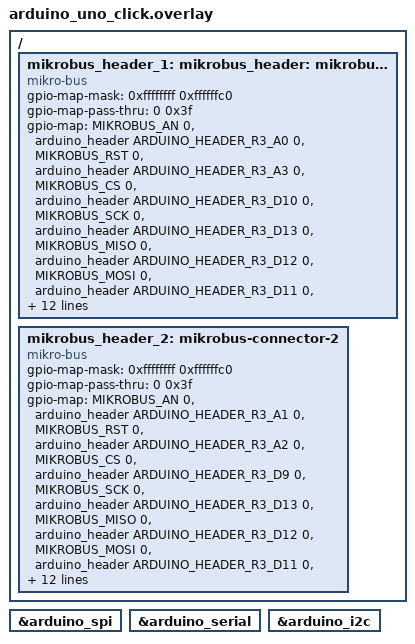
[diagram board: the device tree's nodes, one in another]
/*
 * Copyright (c) 2023 Andriy Gelman
 *
 * SPDX-License-Identifier: Apache-2.0
 */

#include <zephyr/dt-bindings/gpio/arduino-header-r3.h>
#include <zephyr/dt-bindings/gpio/mikro-bus.h>

/ {
	mikrobus_header_1: mikrobus-connector-1 {
		compatible = "mikro-bus";
		#gpio-cells = <2>;
		gpio-map-mask = <0xffffffff 0xffffffc0>;
		gpio-map-pass-thru = <0 0x3f>;
		gpio-map = <MIKROBUS_AN 0 &arduino_header ARDUINO_HEADER_R3_A0 0>,
			   <MIKROBUS_RST 0 &arduino_header ARDUINO_HEADER_R3_A3 0>,
			   <MIKROBUS_CS 0 &arduino_header ARDUINO_HEADER_R3_D10 0>,
			   <MIKROBUS_SCK 0 &arduino_header ARDUINO_HEADER_R3_D13 0>,
			   <MIKROBUS_MISO 0 &arduino_header ARDUINO_HEADER_R3_D12 0>,
			   <MIKROBUS_MOSI 0 &arduino_header ARDUINO_HEADER_R3_D11 0>,
			   /* +3.3V */
			   /* GND */
			   <MIKROBUS_PWM 0 &arduino_header ARDUINO_HEADER_R3_D6 0>,
			   <MIKROBUS_INT 0 &arduino_header ARDUINO_HEADER_R3_D2 0>,
			   <MIKROBUS_RX 0 &arduino_header ARDUINO_HEADER_R3_D0 0>,
			   <MIKROBUS_TX 0 &arduino_header ARDUINO_HEADER_R3_D1 0>,
			   <MIKROBUS_SCL 0 &arduino_header ARDUINO_HEADER_R3_A5 0>,
			   <MIKROBUS_SDA 0 &arduino_header ARDUINO_HEADER_R3_A4 0>;
		/* +5V */
		/* GND */
	};

	mikrobus_header_2: mikrobus-connector-2 {
		compatible = "mikro-bus";
		#gpio-cells = <2>;
		gpio-map-mask = <0xffffffff 0xffffffc0>;
		gpio-map-pass-thru = <0 0x3f>;
		gpio-map = <MIKROBUS_AN 0 &arduino_header ARDUINO_HEADER_R3_A1 0>,
			   <MIKROBUS_RST 0 &arduino_header ARDUINO_HEADER_R3_A2 0>,
			   <MIKROBUS_CS 0 &arduino_header ARDUINO_HEADER_R3_D9 0>,
			   <MIKROBUS_SCK 0 &arduino_header ARDUINO_HEADER_R3_D13 0>,
			   <MIKROBUS_MISO 0 &arduino_header ARDUINO_HEADER_R3_D12 0>,
			   <MIKROBUS_MOSI 0 &arduino_header ARDUINO_HEADER_R3_D11 0>,
			   /* +3.3V */
			   /* GND */
			   <MIKROBUS_PWM 0 &arduino_header ARDUINO_HEADER_R3_D5 0>,
			   <MIKROBUS_INT 0 &arduino_header ARDUINO_HEADER_R3_D3 0>,
			   <MIKROBUS_RX 0 &arduino_header ARDUINO_HEADER_R3_D0 0>,
			   <MIKROBUS_TX 0 &arduino_header ARDUINO_HEADER_R3_D1 0>,
			   <MIKROBUS_SCL 0 &arduino_header ARDUINO_HEADER_R3_A5 0>,
			   <MIKROBUS_SDA 0 &arduino_header ARDUINO_HEADER_R3_A4 0>;
		/* +5V */
		/* GND */
	};
};

mikrobus_spi: &arduino_spi {};

mikrobus_serial: &arduino_serial {};

mikrobus_i2c: &arduino_i2c {};

mikrobus_header: &mikrobus_header_1 {};
